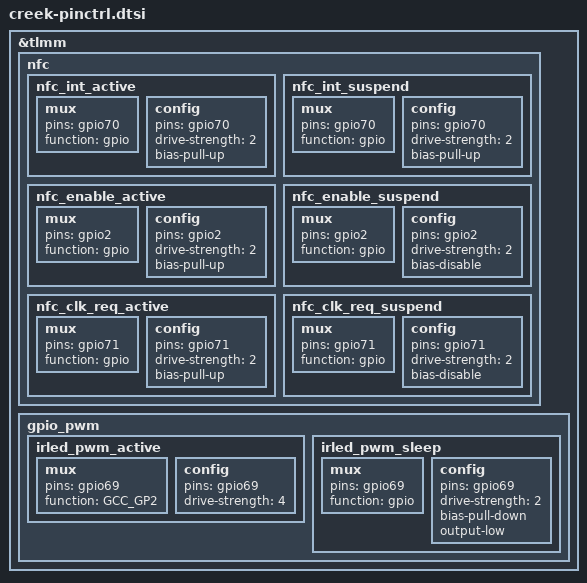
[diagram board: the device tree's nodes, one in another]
/* for creek pinctrl */

&tlmm {
	nfc {
		nfc_int_active: nfc_int_active {
			/* active state */
			mux {
				/* GPIO 70 NFC Read Interrupt */
				pins = "gpio70";
				function = "gpio";
			};

			config {
				pins = "gpio70";
				drive-strength = <2>; /* 2 MA */
				bias-pull-up;
			};
		};

		nfc_int_suspend: nfc_int_suspend {
			/* sleep state */
			mux {
				/* GPIO 70 NFC Read Interrupt */
				pins = "gpio70";
				function = "gpio";
			};

			config {
				pins = "gpio70";
				drive-strength = <2>; /* 2 MA */
				bias-pull-up;
			};
		};

		nfc_enable_active: nfc_enable_active {
			/* active state */
			mux {
				/* 2: Enable */
				pins = "gpio2";
				function = "gpio";
			};

			config {
				pins = "gpio2";
				drive-strength = <2>; /* 2 MA */
				bias-pull-up;
			};
		};

		nfc_enable_suspend: nfc_enable_suspend {
			/* sleep state */
			mux {
				/* 2: Enable */
				pins = "gpio2";
				function = "gpio";
			};

			config {
				pins = "gpio2";
				drive-strength = <2>; /* 2 MA */
				bias-disable;
			};
		};

		nfc_clk_req_active: nfc_clk_req_active {
			/* active state */
			mux {
				/* GPIO 71: NFC CLOCK REQUEST */
				pins = "gpio71";
				function = "gpio";
			};

			config {
				pins = "gpio71";
				drive-strength = <2>; /* 2 MA */
				bias-pull-up;
			};
		};

		nfc_clk_req_suspend: nfc_clk_req_suspend {
			/* sleep state */
			mux {
				/* GPIO 71: NFC CLOCK REQUEST */
				pins = "gpio71";
				function = "gpio";
			};

			config {
				pins = "gpio71";
				drive-strength = <2>; /* 2 MA */
				bias-disable;
			};
		};
	};

	gpio_pwm {
		irled_pwm_active: irled_pwm_active {
			mux {
				pins = "gpio69";
				function = "GCC_GP2";
			};

			config {
				pins = "gpio69";
				drive-strength = <4>;
				// bias-disable; /* NO PULL */
				// output-low;
			};
		};

		irled_pwm_sleep: irled_pwm_sleep {
			mux {
				pins = "gpio69";
				function = "gpio";
			};

			config {
				pins = "gpio69";
				drive-strength = <2>;
				bias-pull-down;
				output-low;
			};
		};
	};
};
